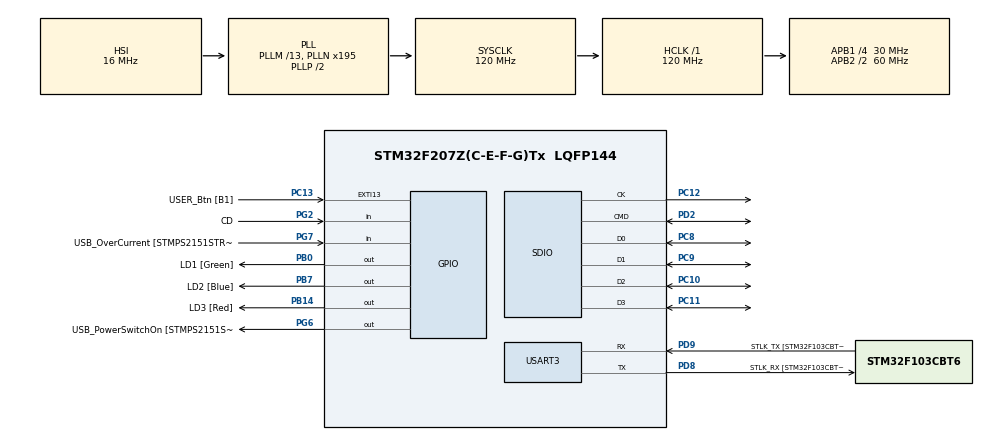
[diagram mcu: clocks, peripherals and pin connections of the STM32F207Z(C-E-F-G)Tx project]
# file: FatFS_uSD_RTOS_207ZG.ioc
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Dma.Request0=SDIO_RX
Dma.Request1=SDIO_TX
Dma.SDIO_RX.0.Direction=DMA_PERIPH_TO_MEMORY
Dma.SDIO_RX.0.FIFOMode=DMA_FIFOMODE_ENABLE
Dma.SDIO_RX.0.FIFOThreshold=DMA_FIFO_THRESHOLD_FULL
Dma.SDIO_RX.0.Instance=DMA2_Stream3
Dma.SDIO_RX.0.MemBurst=DMA_MBURST_INC4
Dma.SDIO_RX.0.MemDataAlignment=DMA_MDATAALIGN_WORD
Dma.SDIO_RX.0.MemInc=DMA_MINC_ENABLE
Dma.SDIO_RX.0.Mode=DMA_PFCTRL
Dma.SDIO_RX.0.PeriphBurst=DMA_PBURST_INC4
Dma.SDIO_RX.0.PeriphDataAlignment=DMA_PDATAALIGN_WORD
Dma.SDIO_RX.0.PeriphInc=DMA_PINC_DISABLE
Dma.SDIO_RX.0.Priority=DMA_PRIORITY_LOW
Dma.SDIO_TX.1.Direction=DMA_MEMORY_TO_PERIPH
Dma.SDIO_TX.1.FIFOMode=DMA_FIFOMODE_ENABLE
Dma.SDIO_TX.1.FIFOThreshold=DMA_FIFO_THRESHOLD_FULL
Dma.SDIO_TX.1.Instance=DMA2_Stream6
Dma.SDIO_TX.1.MemBurst=DMA_MBURST_INC4
Dma.SDIO_TX.1.MemDataAlignment=DMA_MDATAALIGN_WORD
Dma.SDIO_TX.1.MemInc=DMA_MINC_ENABLE
Dma.SDIO_TX.1.Mode=DMA_PFCTRL
Dma.SDIO_TX.1.PeriphBurst=DMA_PBURST_INC4
Dma.SDIO_TX.1.PeriphDataAlignment=DMA_PDATAALIGN_WORD
Dma.SDIO_TX.1.PeriphInc=DMA_PINC_DISABLE
Dma.SDIO_TX.1.Priority=DMA_PRIORITY_LOW
FATFS.BSP.number=1
FATFS._MAX_SS=4096
FATFS._USE_LFN=0
FATFS0.BSP.STBoard=false
FATFS0.BSP.api=Unknown
FATFS0.BSP.i2caddr=0
FATFS0.BSP.instance=PG2
FATFS0.BSP.ip=GPIO
FATFS0.BSP.mode=Input
FATFS0.BSP.name=Detect_SDIO
FATFS0.BSP.solution=PG2
FREERTOS.Mutexes01=myMutex01,Dynamic,NULL
FREERTOS.Tasks01=firstTask,24,128,taskT1,Default,NULL,Dynamic,NULL,NULL;myTask02,8,128,taskT2,Default,NULL,Dynamic,NULL,NULL
FREERTOS.configMINIMAL_STACK_SIZE=128
FREERTOS.configUSE_TRACE_FACILITY=0
Mcu.Family=STM32F2
Mcu.Name=STM32F207Z(C-E-F-G)Tx
Mcu.Package=LQFP144
NVIC.DMA2_Stream3_IRQn=true\:5\:0\:false\:false\:true\:true\:false\:true
NVIC.DMA2_Stream6_IRQn=true\:5\:0\:false\:false\:true\:true\:false\:true
NVIC.PriorityGroup=NVIC_PRIORITYGROUP_4
NVIC.SDIO_IRQn=true\:5\:0\:false\:false\:true\:true\:true\:true
NVIC.TIM1_BRK_TIM9_IRQn=true\:0\:0\:false\:false\:true\:false\:false\:true
NVIC.TimeBase=TIM1_BRK_TIM9_IRQn
NVIC.TimeBaseIP=TIM9
PA10.GPIO_Label=USB_ID
PA10.Signal=USB_OTG_FS_ID
PA11.GPIO_Label=USB_DM
PA11.Signal=USB_OTG_FS_DM
PA12.GPIO_Label=USB_DP
PA12.Signal=USB_OTG_FS_DP
PA13.GPIO_Label=TMS
PA13.Mode=Serial_Wire
PA13.Signal=SYS_JTMS-SWDIO
PA14.GPIO_Label=TCK
PA14.Mode=Serial_Wire
PA14.Signal=SYS_JTCK-SWCLK
PA8.GPIO_Label=USB_SOF [TP1]
PA8.Signal=USB_OTG_FS_SOF
PA9.GPIO_Label=USB_VBUS
PA9.Signal=USB_OTG_FS_VBUS
PB0.GPIO_Label=LD1 [Green]
PB0.Signal=GPIO_Output
PB14.GPIO_Label=LD3 [Red]
PB14.Signal=GPIO_Output
PB3.GPIO_Label=SWO
PB3.Signal=SYS_JTDO-SWO
PB7.GPIO_Label=LD2 [Blue]
PB7.Signal=GPIO_Output
PC10.Mode=SD_4_bits_Wide_bus
PC10.Signal=SDIO_D2
PC11.Mode=SD_4_bits_Wide_bus
PC11.Signal=SDIO_D3
PC12.Mode=SD_4_bits_Wide_bus
PC12.Signal=SDIO_CK
PC13.GPIO_Label=USER_Btn [B1]
PC13.Signal=GPXTI13
PC14-OSC32_IN.Mode=LSE-External-Oscillator
PC14-OSC32_IN.Signal=RCC_OSC32_IN
PC15-OSC32_OUT.Mode=LSE-External-Oscillator
PC15-OSC32_OUT.Signal=RCC_OSC32_OUT
PC8.Mode=SD_4_bits_Wide_bus
PC8.Signal=SDIO_D0
PC9.Mode=SD_4_bits_Wide_bus
PC9.Signal=SDIO_D1
PD2.Mode=SD_4_bits_Wide_bus
PD2.Signal=SDIO_CMD
PD8.GPIO_Label=STLK_RX [STM32F103CBT6_PA3]
PD8.Mode=Asynchronous
PD8.Signal=USART3_TX
PD9.GPIO_Label=STLK_TX [STM32F103CBT6_PA2]
PD9.Mode=Asynchronous
PD9.Signal=USART3_RX
PG2.GPIO_Label=CD
PG2.GPIO_PuPd=GPIO_PULLUP
PG2.Signal=GPIO_Input
PG6.GPIO_Label=USB_PowerSwitchOn [STMPS2151STR_EN]
PG6.Signal=GPIO_Output
PG7.GPIO_Label=USB_OverCurrent [STMPS2151STR_FAULT]
PG7.Signal=GPIO_Input
PH0-OSC_IN.GPIO_Label=MCO [STM32F103CBT6_PA8]
PH0-OSC_IN.Mode=HSE-External-Clock-Source
PH0-OSC_IN.Signal=RCC_OSC_IN
PH1-OSC_OUT.Mode=HSE-External-Clock-Source
PH1-OSC_OUT.Signal=RCC_OSC_OUT
ProjectManager.HeapSize=0x1000
ProjectManager.StackSize=0x1000
ProjectManager.TargetToolchain=STM32CubeIDE
RCC.48MHZClocksFreq_Value=48000000
RCC.AHBFreq_Value=120000000
RCC.APB1CLKDivider=RCC_HCLK_DIV4
RCC.APB1Freq_Value=30000000
RCC.APB1TimFreq_Value=60000000
RCC.APB2CLKDivider=RCC_HCLK_DIV2
RCC.APB2Freq_Value=60000000
RCC.APB2TimFreq_Value=120000000
RCC.CortexFreq_Value=120000000
RCC.HCLKFreq_Value=120000000
RCC.HSE_VALUE=8000000
RCC.HSI_VALUE=16000000
RCC.PLLM=13
RCC.PLLMUL=RCC_PLL_MUL9
RCC.PLLN=195
RCC.PLLQ=5
RCC.PRESCALERUSB=RCC_USBCLKSOURCE_PLL_DIV1_5
RCC.SYSCLKFreq_VALUE=120000000
RCC.SYSCLKSource=RCC_SYSCLKSOURCE_PLLCLK
RCC.SYSCLKSourceVirtual=RCC_SYSCLKSOURCE_PLLCLK
RCC.USBFreq_Value=48000000
RCC.VCOOutputFreq_Value=240000000
SDIO.ClockDiv=3
USART3.VirtualMode=VM_ASYNC
VP_FATFS_VS_SDIO.Mode=SDIO
VP_FREERTOS_VS_CMSIS_V2.Mode=CMSIS_V2
VP_SYS_VS_tim9.Mode=TIM9
board=NUCLEO-F207ZG

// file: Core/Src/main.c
/* USER CODE BEGIN Header */
/**
 ******************************************************************************
 * @file           : main.c
 * @brief          : Main program body
 ******************************************************************************
 * @attention
 *
 * <h2><center>&copy; Copyright (c) 2021 STMicroelectronics.
 * All rights reserved.</center></h2>
 *
 * This software component is licensed by ST under BSD 3-Clause license,
 * the "License"; You may not use this file except in compliance with the
 * License. You may obtain a copy of the License at:
 *                        opensource.org/licenses/BSD-3-Clause
 *
 ******************************************************************************
 */
/* USER CODE END Header */
#include "main.h"
#include "cmsis_os.h"
#include "fatfs.h"

SD_HandleTypeDef hsd;
DMA_HandleTypeDef hdma_sdio_rx;
DMA_HandleTypeDef hdma_sdio_tx;

UART_HandleTypeDef huart3;

/* Definitions for firstTask */
osThreadId_t firstTaskHandle;
const osThreadAttr_t firstTask_attributes =
{ .name = "firstTask", .priority = (osPriority_t) osPriorityNormal,
		.stack_size = 128 * 4 };
/* Definitions for myTask02 */
osThreadId_t myTask02Handle;
const osThreadAttr_t myTask02_attributes =
{ .name = "myTask02", .priority = (osPriority_t) osPriorityLow, .stack_size =
		128 * 4 };
/* Definitions for myMutex01 */
osMutexId_t myMutex01Handle;
const osMutexAttr_t myMutex01_attributes =
{ .name = "myMutex01" };
/* USER CODE BEGIN PV */
FATFS SDFatFs; /* File system object for SD card logical drive */
FIL MyFile; /* File object */
char SDPath[4]; /* SD card logical drive path */

typedef enum
{
	CARD_CONNECTED, CARD_DISCONNECTED,
} SD_ConnectionStateTypeDef;

osMessageQId ConnectionEvent;

static uint8_t isInitialized = 0;
static uint8_t isFsCreated = 0;
uint8_t workBuffer[2 * _MAX_SS];
/* USER CODE END PV */

void SystemClock_Config(void);
static void MX_GPIO_Init(void);
static void MX_DMA_Init(void);
static void MX_USART3_UART_Init(void);
static void MX_SDIO_SD_Init(void);
void taskT1(void *argument);
void taskT2(void *argument);

int main(void)
{

	/* MCU Configuration--------------------------------------------------------*/

	/* Reset of all peripherals, Initializes the Flash interface and the Systick. */
	HAL_Init();

	/* Configure the system clock */
	SystemClock_Config();

	/* Initialize all configured peripherals */
	MX_GPIO_Init();
	MX_DMA_Init();
	MX_USART3_UART_Init();
	MX_SDIO_SD_Init();
	MX_FATFS_Init();

	/* Init scheduler */
	osKernelInitialize();
	/* Create the mutex(es) */
	/* creation of myMutex01 */
	myMutex01Handle = osMutexNew(&myMutex01_attributes);

	/* Create the thread(s) */
	/* creation of firstTask */
	firstTaskHandle = osThreadNew(taskT1, NULL, &firstTask_attributes);

	/* creation of myTask02 */
	myTask02Handle = osThreadNew(taskT2, NULL, &myTask02_attributes);

	/* Start scheduler */
	osKernelStart();

	/* We should never get here as control is now taken by the scheduler */
	/* Infinite loop */
	while (1)
	{

	}
}

void SystemClock_Config(void)
{
	RCC_OscInitTypeDef RCC_OscInitStruct =
	{ 0 };
	RCC_ClkInitTypeDef RCC_ClkInitStruct =
	{ 0 };

	/** Initializes the RCC Oscillators according to the specified parameters
	 * in the RCC_OscInitTypeDef structure.
	 */
	RCC_OscInitStruct.OscillatorType = RCC_OSCILLATORTYPE_HSI;
	RCC_OscInitStruct.HSIState = RCC_HSI_ON;
	RCC_OscInitStruct.HSICalibrationValue = RCC_HSICALIBRATION_DEFAULT;
	RCC_OscInitStruct.PLL.PLLState = RCC_PLL_ON;
	RCC_OscInitStruct.PLL.PLLSource = RCC_PLLSOURCE_HSI;
	RCC_OscInitStruct.PLL.PLLM = 13;
	RCC_OscInitStruct.PLL.PLLN = 195;
	RCC_OscInitStruct.PLL.PLLP = RCC_PLLP_DIV2;
	RCC_OscInitStruct.PLL.PLLQ = 5;
	if (HAL_RCC_OscConfig(&RCC_OscInitStruct) != HAL_OK)
	{
		Error_Handler();
	}
	/** Initializes the CPU, AHB and APB buses clocks
	 */
	RCC_ClkInitStruct.ClockType = RCC_CLOCKTYPE_HCLK | RCC_CLOCKTYPE_SYSCLK
			| RCC_CLOCKTYPE_PCLK1 | RCC_CLOCKTYPE_PCLK2;
	RCC_ClkInitStruct.SYSCLKSource = RCC_SYSCLKSOURCE_PLLCLK;
	RCC_ClkInitStruct.AHBCLKDivider = RCC_SYSCLK_DIV1;
	RCC_ClkInitStruct.APB1CLKDivider = RCC_HCLK_DIV4;
	RCC_ClkInitStruct.APB2CLKDivider = RCC_HCLK_DIV2;

	if (HAL_RCC_ClockConfig(&RCC_ClkInitStruct, FLASH_LATENCY_3) != HAL_OK)
	{
		Error_Handler();
	}
}

static void MX_SDIO_SD_Init(void)
{

	hsd.Instance = SDIO;
	hsd.Init.ClockEdge = SDIO_CLOCK_EDGE_RISING;
	hsd.Init.ClockBypass = SDIO_CLOCK_BYPASS_DISABLE;
	hsd.Init.ClockPowerSave = SDIO_CLOCK_POWER_SAVE_DISABLE;
	hsd.Init.BusWide = SDIO_BUS_WIDE_1B;
	hsd.Init.HardwareFlowControl = SDIO_HARDWARE_FLOW_CONTROL_DISABLE;
	hsd.Init.ClockDiv = 3;

}

static void MX_USART3_UART_Init(void)
{

	huart3.Instance = USART3;
	huart3.Init.BaudRate = 115200;
	huart3.Init.WordLength = UART_WORDLENGTH_8B;
	huart3.Init.StopBits = UART_STOPBITS_1;
	huart3.Init.Parity = UART_PARITY_NONE;
	huart3.Init.Mode = UART_MODE_TX_RX;
	huart3.Init.HwFlowCtl = UART_HWCONTROL_NONE;
	huart3.Init.OverSampling = UART_OVERSAMPLING_16;
	if (HAL_UART_Init(&huart3) != HAL_OK)
	{
		Error_Handler();
	}

}

static void MX_DMA_Init(void)
{

	/* DMA controller clock enable */
	__HAL_RCC_DMA2_CLK_ENABLE();

	/* DMA interrupt init */
	/* DMA2_Stream3_IRQn interrupt configuration */
	HAL_NVIC_SetPriority(DMA2_Stream3_IRQn, 5, 0);
	HAL_NVIC_EnableIRQ(DMA2_Stream3_IRQn);
	/* DMA2_Stream6_IRQn interrupt configuration */
	HAL_NVIC_SetPriority(DMA2_Stream6_IRQn, 5, 0);
	HAL_NVIC_EnableIRQ(DMA2_Stream6_IRQn);

}

static void MX_GPIO_Init(void)
{
	GPIO_InitTypeDef GPIO_InitStruct =
	{ 0 };

	/* GPIO Ports Clock Enable */
	__HAL_RCC_GPIOC_CLK_ENABLE();
	__HAL_RCC_GPIOH_CLK_ENABLE();
	__HAL_RCC_GPIOB_CLK_ENABLE();
	__HAL_RCC_GPIOD_CLK_ENABLE();
	__HAL_RCC_GPIOG_CLK_ENABLE();
	__HAL_RCC_GPIOA_CLK_ENABLE();

	/*Configure GPIO pin Output Level */
	HAL_GPIO_WritePin(GPIOB, LD1_Pin | LD3_Pin | LD2_Pin, GPIO_PIN_RESET);

	/*Configure GPIO pin Output Level */
	HAL_GPIO_WritePin(USB_PowerSwitchOn_GPIO_Port, USB_PowerSwitchOn_Pin,
			GPIO_PIN_RESET);

	/*Configure GPIO pin : USER_Btn_Pin */
	GPIO_InitStruct.Pin = USER_Btn_Pin;
	GPIO_InitStruct.Mode = GPIO_MODE_IT_RISING;
	GPIO_InitStruct.Pull = GPIO_NOPULL;
	HAL_GPIO_Init(USER_Btn_GPIO_Port, &GPIO_InitStruct);

	/*Configure GPIO pins : LD1_Pin LD3_Pin LD2_Pin */
	GPIO_InitStruct.Pin = LD1_Pin | LD3_Pin | LD2_Pin;
	GPIO_InitStruct.Mode = GPIO_MODE_OUTPUT_PP;
	GPIO_InitStruct.Pull = GPIO_NOPULL;
	GPIO_InitStruct.Speed = GPIO_SPEED_FREQ_LOW;
	HAL_GPIO_Init(GPIOB, &GPIO_InitStruct);

	/*Configure GPIO pin : CD_Pin */
	GPIO_InitStruct.Pin = CD_Pin;
	GPIO_InitStruct.Mode = GPIO_MODE_INPUT;
	GPIO_InitStruct.Pull = GPIO_PULLUP;
	HAL_GPIO_Init(CD_GPIO_Port, &GPIO_InitStruct);

	/*Configure GPIO pin : USB_PowerSwitchOn_Pin */
	GPIO_InitStruct.Pin = USB_PowerSwitchOn_Pin;
	GPIO_InitStruct.Mode = GPIO_MODE_OUTPUT_PP;
	GPIO_InitStruct.Pull = GPIO_NOPULL;
	GPIO_InitStruct.Speed = GPIO_SPEED_FREQ_LOW;
	HAL_GPIO_Init(USB_PowerSwitchOn_GPIO_Port, &GPIO_InitStruct);

	/*Configure GPIO pin : USB_OverCurrent_Pin */
	GPIO_InitStruct.Pin = USB_OverCurrent_Pin;
	GPIO_InitStruct.Mode = GPIO_MODE_INPUT;
	GPIO_InitStruct.Pull = GPIO_NOPULL;
	HAL_GPIO_Init(USB_OverCurrent_GPIO_Port, &GPIO_InitStruct);

	/*Configure GPIO pins : USB_SOF_Pin USB_ID_Pin USB_DM_Pin USB_DP_Pin */
	GPIO_InitStruct.Pin = USB_SOF_Pin | USB_ID_Pin | USB_DM_Pin | USB_DP_Pin;
	GPIO_InitStruct.Mode = GPIO_MODE_AF_PP;
	GPIO_InitStruct.Pull = GPIO_NOPULL;
	GPIO_InitStruct.Speed = GPIO_SPEED_FREQ_VERY_HIGH;
	GPIO_InitStruct.Alternate = GPIO_AF10_OTG_FS;
	HAL_GPIO_Init(GPIOA, &GPIO_InitStruct);

	/*Configure GPIO pin : USB_VBUS_Pin */
	GPIO_InitStruct.Pin = USB_VBUS_Pin;
	GPIO_InitStruct.Mode = GPIO_MODE_INPUT;
	GPIO_InitStruct.Pull = GPIO_NOPULL;
	HAL_GPIO_Init(USB_VBUS_GPIO_Port, &GPIO_InitStruct);

}

void taskT1(void *argument)
{
	for (;;)
	{
		osDelay(1);
	}
}

void taskT2(void *argument)
{
	for (;;)
	{
		osDelay(1);
	}
}

void HAL_TIM_PeriodElapsedCallback(TIM_HandleTypeDef *htim)
{
	if (htim->Instance == TIM9)
	{
		HAL_IncTick();
	}
}

void Error_Handler(void)
{
	__disable_irq();
	while (1)
	{
	}
}

/************************ (C) COPYRIGHT STMicroelectronics *****END OF FILE****/
